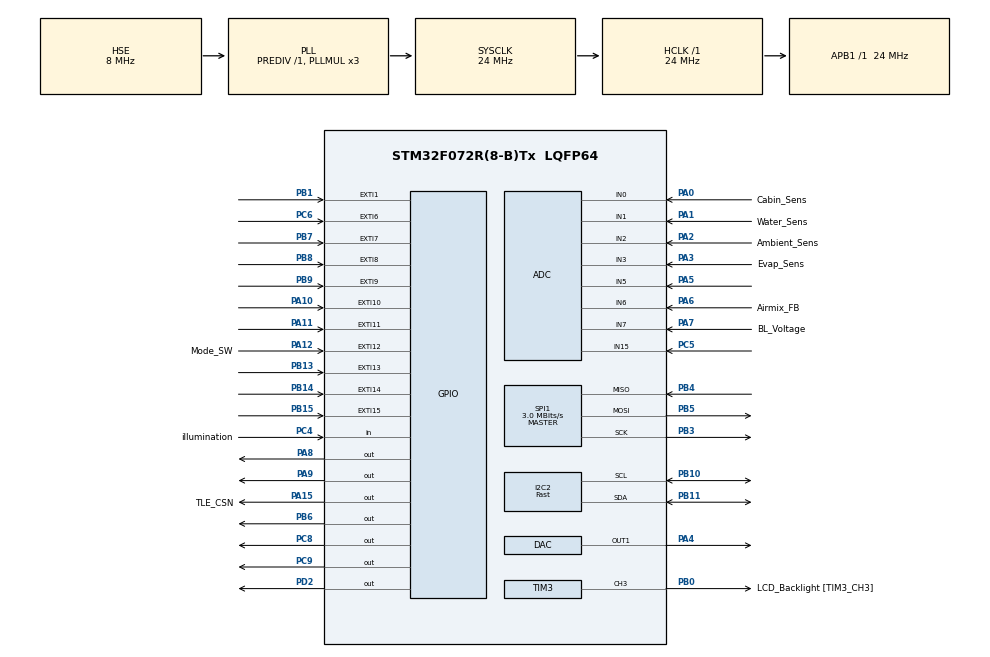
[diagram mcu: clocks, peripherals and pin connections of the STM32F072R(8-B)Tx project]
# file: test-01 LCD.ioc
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ADC.ClockPrescaler=ADC_CLOCK_SYNC_PCLK_DIV4
ADC.ContinuousConvMode=ENABLE
ADC.DMAContinuousRequests=ENABLE
ADC.ExternalTrigConv=ADC_EXTERNALTRIGCONV_T1_TRGO
ADC.Overrun=ADC_OVR_DATA_OVERWRITTEN
ADC.SamplingTime=ADC_SAMPLETIME_239CYCLES_5
Dma.ADC.0.Direction=DMA_PERIPH_TO_MEMORY
Dma.ADC.0.Instance=DMA1_Channel1
Dma.ADC.0.MemDataAlignment=DMA_MDATAALIGN_HALFWORD
Dma.ADC.0.MemInc=DMA_MINC_ENABLE
Dma.ADC.0.Mode=DMA_CIRCULAR
Dma.ADC.0.PeriphDataAlignment=DMA_PDATAALIGN_HALFWORD
Dma.ADC.0.PeriphInc=DMA_PINC_DISABLE
Dma.ADC.0.Priority=DMA_PRIORITY_LOW
Dma.Request0=ADC
I2C2.I2C_Speed_Mode=I2C_Fast
I2C2.Timing=0x00200C28
Mcu.Family=STM32F0
Mcu.Name=STM32F072R(8-B)Tx
Mcu.Package=LQFP64
NVIC.ADC1_COMP_IRQn=true\:0\:0\:false\:false\:true\:true\:true\:true
NVIC.DMA1_Channel1_IRQn=true\:0\:0\:true\:false\:true\:false\:true\:true
NVIC.EXTI0_1_IRQn=true\:0\:0\:false\:false\:true\:true\:true\:true
NVIC.EXTI4_15_IRQn=true\:0\:0\:false\:false\:true\:true\:true\:true
NVIC.TIM14_IRQn=true\:0\:0\:false\:false\:true\:true\:true\:true
NVIC.TIM15_IRQn=true\:0\:0\:false\:false\:true\:true\:true\:true
NVIC.TIM2_IRQn=true\:0\:0\:false\:false\:true\:true\:true\:true
NVIC.TIM6_DAC_IRQn=true\:0\:0\:false\:false\:true\:true\:true\:true
NVIC.TIM7_IRQn=true\:0\:0\:false\:false\:true\:true\:true\:true
PA0.GPIO_Label=Cabin_Sens
PA0.Mode=IN0
PA0.Signal=ADC_IN0
PA1.GPIO_Label=Water_Sens
PA1.Mode=IN1
PA1.Signal=ADC_IN1
PA10.GPIO_ModeDefaultEXTI=GPIO_MODE_IT_FALLING
PA10.GPIO_PuPd=GPIO_PULLUP
PA10.Signal=GPXTI10
PA11.GPIO_ModeDefaultEXTI=GPIO_MODE_IT_FALLING
PA11.GPIO_PuPd=GPIO_PULLUP
PA11.Signal=GPXTI11
PA12.GPIO_Label=Mode_SW
PA12.GPIO_ModeDefaultEXTI=GPIO_MODE_IT_FALLING
PA12.GPIO_PuPd=GPIO_PULLUP
PA12.Signal=GPXTI12
PA13.Mode=Serial_Wire
PA13.Signal=SYS_SWDIO
PA14.Mode=Serial_Wire
PA14.Signal=SYS_SWCLK
PA15.GPIO_Label=TLE_CSN
PA15.Signal=GPIO_Output
PA2.GPIO_Label=Ambient_Sens
PA2.Mode=IN2
PA2.Signal=ADC_IN2
PA3.GPIO_Label=Evap_Sens
PA3.Mode=IN3
PA3.Signal=ADC_IN3
PA4.Signal=COMP_DAC1_group
PA5.Mode=IN5
PA5.Signal=ADC_IN5
PA6.GPIO_Label=Airmix_FB
PA6.Mode=IN6
PA6.Signal=ADC_IN6
PA7.GPIO_Label=BL_Voltage
PA7.Mode=IN7
PA7.Signal=ADC_IN7
PA8.Signal=GPIO_Output
PA9.Signal=GPIO_Output
PB0.GPIO_Label=LCD_Backlight [TIM3_CH3]
PB0.Signal=S_TIM3_CH3
PB1.GPIO_ModeDefaultEXTI=GPIO_MODE_IT_FALLING
PB1.GPIO_PuPd=GPIO_PULLUP
PB1.Signal=GPXTI1
PB10.Mode=I2C
PB10.Signal=I2C2_SCL
PB11.Mode=I2C
PB11.Signal=I2C2_SDA
PB13.GPIO_ModeDefaultEXTI=GPIO_MODE_IT_FALLING
PB13.GPIO_PuPd=GPIO_PULLUP
PB13.Signal=GPXTI13
PB14.GPIO_ModeDefaultEXTI=GPIO_MODE_IT_FALLING
PB14.GPIO_PuPd=GPIO_PULLUP
PB14.Signal=GPXTI14
PB15.GPIO_ModeDefaultEXTI=GPIO_MODE_IT_FALLING
PB15.GPIO_PuPd=GPIO_PULLUP
PB15.Signal=GPXTI15
PB3.Mode=Full_Duplex_Master
PB3.Signal=SPI1_SCK
PB4.Mode=Full_Duplex_Master
PB4.Signal=SPI1_MISO
PB5.Mode=Full_Duplex_Master
PB5.Signal=SPI1_MOSI
PB6.Signal=GPIO_Output
PB7.GPIO_ModeDefaultEXTI=GPIO_MODE_IT_FALLING
PB7.GPIO_PuPd=GPIO_PULLUP
PB7.Signal=GPXTI7
PB8.GPIO_ModeDefaultEXTI=GPIO_MODE_IT_FALLING
PB8.GPIO_PuPd=GPIO_PULLUP
PB8.Signal=GPXTI8
PB9.GPIO_ModeDefaultEXTI=GPIO_MODE_IT_FALLING
PB9.GPIO_PuPd=GPIO_PULLUP
PB9.Signal=GPXTI9
PC4.GPIO_Label=illumination
PC4.Signal=GPIO_Input
PC5.Mode=IN15
PC5.Signal=ADC_IN15
PC6.GPIO_ModeDefaultEXTI=GPIO_MODE_IT_FALLING
PC6.GPIO_PuPd=GPIO_PULLUP
PC6.Signal=GPXTI6
PC8.Signal=GPIO_Output
PC9.Signal=GPIO_Output
PD2.Signal=GPIO_Output
PF0-OSC_IN.Mode=HSE-External-Oscillator
PF0-OSC_IN.Signal=RCC_OSC_IN
PF1-OSC_OUT.Mode=HSE-External-Oscillator
PF1-OSC_OUT.Signal=RCC_OSC_OUT
ProjectManager.HeapSize=0x200
ProjectManager.StackSize=0x400
ProjectManager.TargetToolchain=MDK-ARM V5.32
RCC.AHBFreq_Value=24000000
RCC.APB1Freq_Value=24000000
RCC.APB1TimFreq_Value=24000000
RCC.HCLKFreq_Value=24000000
RCC.PLLMUL=RCC_PLL_MUL3
RCC.PLLSourceVirtual=RCC_PLLSOURCE_HSE
RCC.SYSCLKFreq_VALUE=24000000
RCC.SYSCLKSource=RCC_SYSCLKSOURCE_PLLCLK
SH.COMP_DAC1_group.0=DAC_OUT1,DAC_OUT1
SH.S_TIM3_CH3.0=TIM3_CH3,PWM Generation3 CH3
SPI1.BaudRatePrescaler=SPI_BAUDRATEPRESCALER_8
SPI1.CLKPhase=SPI_PHASE_2EDGE
SPI1.CalculateBaudRate=3.0 MBits/s
SPI1.DataSize=SPI_DATASIZE_8BIT
SPI1.Direction=SPI_DIRECTION_2LINES
SPI1.FirstBit=SPI_FIRSTBIT_LSB
SPI1.Mode=SPI_MODE_MASTER
SPI1.VirtualType=VM_MASTER
TIM1.Period=100-1
TIM1.Prescaler=2400-1
TIM1.TIM_MasterOutputTrigger=TIM_TRGO_UPDATE
TIM14.Period=5000-1
TIM14.Prescaler=24000-1
TIM15.Period=3000-1
TIM15.Prescaler=24000-1
TIM2.Period=840000-1
TIM2.Prescaler=24000-1
TIM3.Channel-PWM\ Generation3\ CH3=TIM_CHANNEL_3
TIM3.Period=100-1
TIM3.Prescaler=240-1
TIM6.Period=15000-1
TIM6.Prescaler=24000-1
TIM7.Period=15000-1
TIM7.Prescaler=24000-1
VP_TIM14_VS_ClockSourceINT.Mode=Enable_Timer
VP_TIM15_VS_ClockSourceINT.Mode=Internal
VP_TIM1_VS_ClockSourceINT.Mode=Internal
VP_TIM2_VS_ClockSourceINT.Mode=Internal
VP_TIM3_VS_ClockSourceINT.Mode=Internal
VP_TIM6_VS_ClockSourceINT.Mode=Enable_Timer
VP_TIM7_VS_ClockSourceINT.Mode=Enable_Timer
board=custom

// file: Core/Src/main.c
/* USER CODE BEGIN Header */
/**
  ******************************************************************************
  * @file           : main.c
  * @brief          : Main program body
  ******************************************************************************
  * @attention
  *
  * Copyright (c) 2022 STMicroelectronics.
  * All rights reserved.
  *
  * This software is licensed under terms that can be found in the LICENSE file
  * in the root directory of this software component.
  * If no LICENSE file comes with this software, it is provided AS-IS.
  *
  ******************************************************************************
  */
/* USER CODE END Header */
#include "main.h"

/* USER CODE BEGIN Includes */
//#include "SP100_lcd.h"
#include "SP100_atc_ccu.h"

/* USER CODE END Includes */

 ADC_HandleTypeDef hadc;
DMA_HandleTypeDef hdma_adc;

DAC_HandleTypeDef hdac;

I2C_HandleTypeDef hi2c2;

SPI_HandleTypeDef hspi1;

TIM_HandleTypeDef htim1;
TIM_HandleTypeDef htim2;
TIM_HandleTypeDef htim3;
TIM_HandleTypeDef htim6;
TIM_HandleTypeDef htim7;
TIM_HandleTypeDef htim14;
TIM_HandleTypeDef htim15;

void SystemClock_Config(void);
static void MX_GPIO_Init(void);
static void MX_I2C2_Init(void);
static void MX_TIM3_Init(void);
static void MX_ADC_Init(void);
static void MX_DMA_Init(void);
static void MX_SPI1_Init(void);
static void MX_DAC_Init(void);
static void MX_TIM1_Init(void);
static void MX_TIM6_Init(void);
static void MX_TIM7_Init(void);
static void MX_TIM14_Init(void);
static void MX_TIM2_Init(void);
static void MX_TIM15_Init(void);

int main(void)
{
  /* USER CODE BEGIN 1 */

	// Agha Ye nokte kheyli mohem:7
	// 	DMA initesh bayad ghable ADC bashe...!!!!!!!
	MX_DMA_Init();
  /* USER CODE END 1 */

  /* MCU Configuration--------------------------------------------------------*/

  /* Reset of all peripherals, Initializes the Flash interface and the Systick. */
  HAL_Init();

  /* Configure the system clock */
  SystemClock_Config();

  /* Initialize all configured peripherals */
  MX_GPIO_Init();
  MX_I2C2_Init();
  MX_TIM3_Init();
  MX_ADC_Init();
  MX_DMA_Init();
  MX_SPI1_Init();
  MX_DAC_Init();
  MX_TIM1_Init();
  MX_TIM6_Init();
  MX_TIM7_Init();
  MX_TIM14_Init();
  MX_TIM2_Init();
  MX_TIM15_Init();
  /* USER CODE BEGIN 2 */
	//SP100_LCD_Init();
	//SP100_TLE_Init();
	SP100_CCU_Init();
	SP100_CCU_Infinite_Loop();
  /* USER CODE END 2 */

  /* Infinite loop */
  while (1)
  {

  }
}

void SystemClock_Config(void)
{
  RCC_OscInitTypeDef RCC_OscInitStruct = {0};
  RCC_ClkInitTypeDef RCC_ClkInitStruct = {0};

  /** Initializes the RCC Oscillators according to the specified parameters
  * in the RCC_OscInitTypeDef structure.
  */
  RCC_OscInitStruct.OscillatorType = RCC_OSCILLATORTYPE_HSE;
  RCC_OscInitStruct.HSEState = RCC_HSE_ON;
  RCC_OscInitStruct.PLL.PLLState = RCC_PLL_ON;
  RCC_OscInitStruct.PLL.PLLSource = RCC_PLLSOURCE_HSE;
  RCC_OscInitStruct.PLL.PLLMUL = RCC_PLL_MUL3;
  RCC_OscInitStruct.PLL.PREDIV = RCC_PREDIV_DIV1;
  if (HAL_RCC_OscConfig(&RCC_OscInitStruct) != HAL_OK)
  {
    Error_Handler();
  }

  /** Initializes the CPU, AHB and APB buses clocks
  */
  RCC_ClkInitStruct.ClockType = RCC_CLOCKTYPE_HCLK|RCC_CLOCKTYPE_SYSCLK
                              |RCC_CLOCKTYPE_PCLK1;
  RCC_ClkInitStruct.SYSCLKSource = RCC_SYSCLKSOURCE_PLLCLK;
  RCC_ClkInitStruct.AHBCLKDivider = RCC_SYSCLK_DIV1;
  RCC_ClkInitStruct.APB1CLKDivider = RCC_HCLK_DIV1;

  if (HAL_RCC_ClockConfig(&RCC_ClkInitStruct, FLASH_LATENCY_0) != HAL_OK)
  {
    Error_Handler();
  }
}

static void MX_ADC_Init(void)
{

  ADC_ChannelConfTypeDef sConfig = {0};

  /** Configure the global features of the ADC (Clock, Resolution, Data Alignment and number of conversion)
  */
  hadc.Instance = ADC1;
  hadc.Init.ClockPrescaler = ADC_CLOCK_SYNC_PCLK_DIV4;
  hadc.Init.Resolution = ADC_RESOLUTION_12B;
  hadc.Init.DataAlign = ADC_DATAALIGN_RIGHT;
  hadc.Init.ScanConvMode = ADC_SCAN_DIRECTION_FORWARD;
  hadc.Init.EOCSelection = ADC_EOC_SINGLE_CONV;
  hadc.Init.LowPowerAutoWait = DISABLE;
  hadc.Init.LowPowerAutoPowerOff = DISABLE;
  hadc.Init.ContinuousConvMode = ENABLE;
  hadc.Init.DiscontinuousConvMode = DISABLE;
  hadc.Init.ExternalTrigConv = ADC_EXTERNALTRIGCONV_T1_TRGO;
  hadc.Init.ExternalTrigConvEdge = ADC_EXTERNALTRIGCONVEDGE_RISING;
  hadc.Init.DMAContinuousRequests = ENABLE;
  hadc.Init.Overrun = ADC_OVR_DATA_OVERWRITTEN;
  if (HAL_ADC_Init(&hadc) != HAL_OK)
  {
    Error_Handler();
  }

  /** Configure for the selected ADC regular channel to be converted.
  */
  sConfig.Channel = ADC_CHANNEL_0;
  sConfig.Rank = ADC_RANK_CHANNEL_NUMBER;
  sConfig.SamplingTime = ADC_SAMPLETIME_239CYCLES_5;
  if (HAL_ADC_ConfigChannel(&hadc, &sConfig) != HAL_OK)
  {
    Error_Handler();
  }

  /** Configure for the selected ADC regular channel to be converted.
  */
  sConfig.Channel = ADC_CHANNEL_1;
  if (HAL_ADC_ConfigChannel(&hadc, &sConfig) != HAL_OK)
  {
    Error_Handler();
  }

  /** Configure for the selected ADC regular channel to be converted.
  */
  sConfig.Channel = ADC_CHANNEL_2;
  if (HAL_ADC_ConfigChannel(&hadc, &sConfig) != HAL_OK)
  {
    Error_Handler();
  }

  /** Configure for the selected ADC regular channel to be converted.
  */
  sConfig.Channel = ADC_CHANNEL_3;
  if (HAL_ADC_ConfigChannel(&hadc, &sConfig) != HAL_OK)
  {
    Error_Handler();
  }

  /** Configure for the selected ADC regular channel to be converted.
  */
  sConfig.Channel = ADC_CHANNEL_5;
  if (HAL_ADC_ConfigChannel(&hadc, &sConfig) != HAL_OK)
  {
    Error_Handler();
  }

  /** Configure for the selected ADC regular channel to be converted.
  */
  sConfig.Channel = ADC_CHANNEL_6;
  if (HAL_ADC_ConfigChannel(&hadc, &sConfig) != HAL_OK)
  {
    Error_Handler();
  }

  /** Configure for the selected ADC regular channel to be converted.
  */
  sConfig.Channel = ADC_CHANNEL_7;
  if (HAL_ADC_ConfigChannel(&hadc, &sConfig) != HAL_OK)
  {
    Error_Handler();
  }

  /** Configure for the selected ADC regular channel to be converted.
  */
  sConfig.Channel = ADC_CHANNEL_15;
  if (HAL_ADC_ConfigChannel(&hadc, &sConfig) != HAL_OK)
  {
    Error_Handler();
  }

}

static void MX_DAC_Init(void)
{

  DAC_ChannelConfTypeDef sConfig = {0};

  /** DAC Initialization
  */
  hdac.Instance = DAC;
  if (HAL_DAC_Init(&hdac) != HAL_OK)
  {
    Error_Handler();
  }

  /** DAC channel OUT1 config
  */
  sConfig.DAC_Trigger = DAC_TRIGGER_NONE;
  sConfig.DAC_OutputBuffer = DAC_OUTPUTBUFFER_ENABLE;
  if (HAL_DAC_ConfigChannel(&hdac, &sConfig, DAC_CHANNEL_1) != HAL_OK)
  {
    Error_Handler();
  }

}

static void MX_I2C2_Init(void)
{

  hi2c2.Instance = I2C2;
  hi2c2.Init.Timing = 0x00200C28;
  hi2c2.Init.OwnAddress1 = 0;
  hi2c2.Init.AddressingMode = I2C_ADDRESSINGMODE_7BIT;
  hi2c2.Init.DualAddressMode = I2C_DUALADDRESS_DISABLE;
  hi2c2.Init.OwnAddress2 = 0;
  hi2c2.Init.OwnAddress2Masks = I2C_OA2_NOMASK;
  hi2c2.Init.GeneralCallMode = I2C_GENERALCALL_DISABLE;
  hi2c2.Init.NoStretchMode = I2C_NOSTRETCH_DISABLE;
  if (HAL_I2C_Init(&hi2c2) != HAL_OK)
  {
    Error_Handler();
  }

  /** Configure Analogue filter
  */
  if (HAL_I2CEx_ConfigAnalogFilter(&hi2c2, I2C_ANALOGFILTER_ENABLE) != HAL_OK)
  {
    Error_Handler();
  }

  /** Configure Digital filter
  */
  if (HAL_I2CEx_ConfigDigitalFilter(&hi2c2, 0) != HAL_OK)
  {
    Error_Handler();
  }

}

static void MX_SPI1_Init(void)
{

  /* SPI1 parameter configuration*/
  hspi1.Instance = SPI1;
  hspi1.Init.Mode = SPI_MODE_MASTER;
  hspi1.Init.Direction = SPI_DIRECTION_2LINES;
  hspi1.Init.DataSize = SPI_DATASIZE_8BIT;
  hspi1.Init.CLKPolarity = SPI_POLARITY_LOW;
  hspi1.Init.CLKPhase = SPI_PHASE_2EDGE;
  hspi1.Init.NSS = SPI_NSS_SOFT;
  hspi1.Init.BaudRatePrescaler = SPI_BAUDRATEPRESCALER_8;
  hspi1.Init.FirstBit = SPI_FIRSTBIT_LSB;
  hspi1.Init.TIMode = SPI_TIMODE_DISABLE;
  hspi1.Init.CRCCalculation = SPI_CRCCALCULATION_DISABLE;
  hspi1.Init.CRCPolynomial = 7;
  hspi1.Init.CRCLength = SPI_CRC_LENGTH_DATASIZE;
  hspi1.Init.NSSPMode = SPI_NSS_PULSE_DISABLE;
  if (HAL_SPI_Init(&hspi1) != HAL_OK)
  {
    Error_Handler();
  }

}

static void MX_TIM1_Init(void)
{

  TIM_ClockConfigTypeDef sClockSourceConfig = {0};
  TIM_MasterConfigTypeDef sMasterConfig = {0};

  htim1.Instance = TIM1;
  htim1.Init.Prescaler = 2400-1;
  htim1.Init.CounterMode = TIM_COUNTERMODE_UP;
  htim1.Init.Period = 100-1;
  htim1.Init.ClockDivision = TIM_CLOCKDIVISION_DIV1;
  htim1.Init.RepetitionCounter = 0;
  htim1.Init.AutoReloadPreload = TIM_AUTORELOAD_PRELOAD_DISABLE;
  if (HAL_TIM_Base_Init(&htim1) != HAL_OK)
  {
    Error_Handler();
  }
  sClockSourceConfig.ClockSource = TIM_CLOCKSOURCE_INTERNAL;
  if (HAL_TIM_ConfigClockSource(&htim1, &sClockSourceConfig) != HAL_OK)
  {
    Error_Handler();
  }
  sMasterConfig.MasterOutputTrigger = TIM_TRGO_UPDATE;
  sMasterConfig.MasterSlaveMode = TIM_MASTERSLAVEMODE_DISABLE;
  if (HAL_TIMEx_MasterConfigSynchronization(&htim1, &sMasterConfig) != HAL_OK)
  {
    Error_Handler();
  }

}

static void MX_TIM2_Init(void)
{

  TIM_ClockConfigTypeDef sClockSourceConfig = {0};
  TIM_MasterConfigTypeDef sMasterConfig = {0};

  htim2.Instance = TIM2;
  htim2.Init.Prescaler = 24000-1;
  htim2.Init.CounterMode = TIM_COUNTERMODE_UP;
  htim2.Init.Period = 840000-1;
  htim2.Init.ClockDivision = TIM_CLOCKDIVISION_DIV1;
  htim2.Init.AutoReloadPreload = TIM_AUTORELOAD_PRELOAD_DISABLE;
  if (HAL_TIM_Base_Init(&htim2) != HAL_OK)
  {
    Error_Handler();
  }
  sClockSourceConfig.ClockSource = TIM_CLOCKSOURCE_INTERNAL;
  if (HAL_TIM_ConfigClockSource(&htim2, &sClockSourceConfig) != HAL_OK)
  {
    Error_Handler();
  }
  sMasterConfig.MasterOutputTrigger = TIM_TRGO_RESET;
  sMasterConfig.MasterSlaveMode = TIM_MASTERSLAVEMODE_DISABLE;
  if (HAL_TIMEx_MasterConfigSynchronization(&htim2, &sMasterConfig) != HAL_OK)
  {
    Error_Handler();
  }

}

static void MX_TIM3_Init(void)
{

  TIM_ClockConfigTypeDef sClockSourceConfig = {0};
  TIM_MasterConfigTypeDef sMasterConfig = {0};
  TIM_OC_InitTypeDef sConfigOC = {0};

  htim3.Instance = TIM3;
  htim3.Init.Prescaler = 240-1;
  htim3.Init.CounterMode = TIM_COUNTERMODE_UP;
  htim3.Init.Period = 100-1;
  htim3.Init.ClockDivision = TIM_CLOCKDIVISION_DIV1;
  htim3.Init.AutoReloadPreload = TIM_AUTORELOAD_PRELOAD_DISABLE;
  if (HAL_TIM_Base_Init(&htim3) != HAL_OK)
  {
    Error_Handler();
  }
  sClockSourceConfig.ClockSource = TIM_CLOCKSOURCE_INTERNAL;
  if (HAL_TIM_ConfigClockSource(&htim3, &sClockSourceConfig) != HAL_OK)
  {
    Error_Handler();
  }
  if (HAL_TIM_PWM_Init(&htim3) != HAL_OK)
  {
    Error_Handler();
  }
  sMasterConfig.MasterOutputTrigger = TIM_TRGO_RESET;
  sMasterConfig.MasterSlaveMode = TIM_MASTERSLAVEMODE_DISABLE;
  if (HAL_TIMEx_MasterConfigSynchronization(&htim3, &sMasterConfig) != HAL_OK)
  {
    Error_Handler();
  }
  sConfigOC.OCMode = TIM_OCMODE_PWM1;
  sConfigOC.Pulse = 0;
  sConfigOC.OCPolarity = TIM_OCPOLARITY_HIGH;
  sConfigOC.OCFastMode = TIM_OCFAST_DISABLE;
  if (HAL_TIM_PWM_ConfigChannel(&htim3, &sConfigOC, TIM_CHANNEL_3) != HAL_OK)
  {
    Error_Handler();
  }
  HAL_TIM_MspPostInit(&htim3);

}

static void MX_TIM6_Init(void)
{

  TIM_MasterConfigTypeDef sMasterConfig = {0};

  htim6.Instance = TIM6;
  htim6.Init.Prescaler = 24000-1;
  htim6.Init.CounterMode = TIM_COUNTERMODE_UP;
  htim6.Init.Period = 15000-1;
  htim6.Init.AutoReloadPreload = TIM_AUTORELOAD_PRELOAD_DISABLE;
  if (HAL_TIM_Base_Init(&htim6) != HAL_OK)
  {
    Error_Handler();
  }
  sMasterConfig.MasterOutputTrigger = TIM_TRGO_RESET;
  sMasterConfig.MasterSlaveMode = TIM_MASTERSLAVEMODE_DISABLE;
  if (HAL_TIMEx_MasterConfigSynchronization(&htim6, &sMasterConfig) != HAL_OK)
  {
    Error_Handler();
  }

}

static void MX_TIM7_Init(void)
{

  TIM_MasterConfigTypeDef sMasterConfig = {0};

  htim7.Instance = TIM7;
  htim7.Init.Prescaler = 24000-1;
  htim7.Init.CounterMode = TIM_COUNTERMODE_UP;
  htim7.Init.Period = 15000-1;
  htim7.Init.AutoReloadPreload = TIM_AUTORELOAD_PRELOAD_DISABLE;
  if (HAL_TIM_Base_Init(&htim7) != HAL_OK)
  {
    Error_Handler();
  }
  sMasterConfig.MasterOutputTrigger = TIM_TRGO_RESET;
  sMasterConfig.MasterSlaveMode = TIM_MASTERSLAVEMODE_DISABLE;
  if (HAL_TIMEx_MasterConfigSynchronization(&htim7, &sMasterConfig) != HAL_OK)
  {
    Error_Handler();
  }

}

static void MX_TIM14_Init(void)
{

  htim14.Instance = TIM14;
  htim14.Init.Prescaler = 24000-1;
  htim14.Init.CounterMode = TIM_COUNTERMODE_UP;
  htim14.Init.Period = 5000-1;
  htim14.Init.ClockDivision = TIM_CLOCKDIVISION_DIV1;
  htim14.Init.AutoReloadPreload = TIM_AUTORELOAD_PRELOAD_DISABLE;
  if (HAL_TIM_Base_Init(&htim14) != HAL_OK)
  {
    Error_Handler();
  }

}

static void MX_TIM15_Init(void)
{

  TIM_ClockConfigTypeDef sClockSourceConfig = {0};
  TIM_MasterConfigTypeDef sMasterConfig = {0};

  htim15.Instance = TIM15;
  htim15.Init.Prescaler = 24000-1;
  htim15.Init.CounterMode = TIM_COUNTERMODE_UP;
  htim15.Init.Period = 3000-1;
  htim15.Init.ClockDivision = TIM_CLOCKDIVISION_DIV1;
  htim15.Init.RepetitionCounter = 0;
  htim15.Init.AutoReloadPreload = TIM_AUTORELOAD_PRELOAD_DISABLE;
  if (HAL_TIM_Base_Init(&htim15) != HAL_OK)
  {
    Error_Handler();
  }
  sClockSourceConfig.ClockSource = TIM_CLOCKSOURCE_INTERNAL;
  if (HAL_TIM_ConfigClockSource(&htim15, &sClockSourceConfig) != HAL_OK)
  {
    Error_Handler();
  }
  sMasterConfig.MasterOutputTrigger = TIM_TRGO_RESET;
  sMasterConfig.MasterSlaveMode = TIM_MASTERSLAVEMODE_DISABLE;
  if (HAL_TIMEx_MasterConfigSynchronization(&htim15, &sMasterConfig) != HAL_OK)
  {
    Error_Handler();
  }

}

static void MX_DMA_Init(void)
{

  /* DMA controller clock enable */
  __HAL_RCC_DMA1_CLK_ENABLE();

  /* DMA interrupt init */
  /* DMA1_Channel1_IRQn interrupt configuration */
  HAL_NVIC_SetPriority(DMA1_Channel1_IRQn, 0, 0);
  HAL_NVIC_EnableIRQ(DMA1_Channel1_IRQn);

}

static void MX_GPIO_Init(void)
{
  GPIO_InitTypeDef GPIO_InitStruct = {0};

  /* GPIO Ports Clock Enable */
  __HAL_RCC_GPIOF_CLK_ENABLE();
  __HAL_RCC_GPIOA_CLK_ENABLE();
  __HAL_RCC_GPIOC_CLK_ENABLE();
  __HAL_RCC_GPIOB_CLK_ENABLE();
  __HAL_RCC_GPIOD_CLK_ENABLE();

  /*Configure GPIO pin Output Level */
  HAL_GPIO_WritePin(GPIOC, GPIO_PIN_8|GPIO_PIN_9, GPIO_PIN_RESET);

  /*Configure GPIO pin Output Level */
  HAL_GPIO_WritePin(GPIOA, GPIO_PIN_8|GPIO_PIN_9|TLE_CSN_Pin, GPIO_PIN_RESET);

  /*Configure GPIO pin Output Level */
  HAL_GPIO_WritePin(GPIOD, GPIO_PIN_2, GPIO_PIN_RESET);

  /*Configure GPIO pin Output Level */
  HAL_GPIO_WritePin(GPIOB, GPIO_PIN_6, GPIO_PIN_RESET);

  /*Configure GPIO pin : illumination_Pin */
  GPIO_InitStruct.Pin = illumination_Pin;
  GPIO_InitStruct.Mode = GPIO_MODE_INPUT;
  GPIO_InitStruct.Pull = GPIO_NOPULL;
  HAL_GPIO_Init(illumination_GPIO_Port, &GPIO_InitStruct);

  /*Configure GPIO pins : PB1 PB13 PB14 PB15
                           PB7 PB8 PB9 */
  GPIO_InitStruct.Pin = GPIO_PIN_1|GPIO_PIN_13|GPIO_PIN_14|GPIO_PIN_15
                          |GPIO_PIN_7|GPIO_PIN_8|GPIO_PIN_9;
  GPIO_InitStruct.Mode = GPIO_MODE_IT_FALLING;
  GPIO_InitStruct.Pull = GPIO_PULLUP;
  HAL_GPIO_Init(GPIOB, &GPIO_InitStruct);

  /*Configure GPIO pin : PC6 */
  GPIO_InitStruct.Pin = GPIO_PIN_6;
  GPIO_InitStruct.Mode = GPIO_MODE_IT_FALLING;
  GPIO_InitStruct.Pull = GPIO_PULLUP;
  HAL_GPIO_Init(GPIOC, &GPIO_InitStruct);

  /*Configure GPIO pins : PC8 PC9 */
  GPIO_InitStruct.Pin = GPIO_PIN_8|GPIO_PIN_9;
  GPIO_InitStruct.Mode = GPIO_MODE_OUTPUT_PP;
  GPIO_InitStruct.Pull = GPIO_NOPULL;
  GPIO_InitStruct.Speed = GPIO_SPEED_FREQ_LOW;
  HAL_GPIO_Init(GPIOC, &GPIO_InitStruct);

  /*Configure GPIO pins : PA8 PA9 TLE_CSN_Pin */
  GPIO_InitStruct.Pin = GPIO_PIN_8|GPIO_PIN_9|TLE_CSN_Pin;
  GPIO_InitStruct.Mode = GPIO_MODE_OUTPUT_PP;
  GPIO_InitStruct.Pull = GPIO_NOPULL;
  GPIO_InitStruct.Speed = GPIO_SPEED_FREQ_LOW;
  HAL_GPIO_Init(GPIOA, &GPIO_InitStruct);

  /*Configure GPIO pins : PA10 PA11 Mode_SW_Pin */
  GPIO_InitStruct.Pin = GPIO_PIN_10|GPIO_PIN_11|Mode_SW_Pin;
  GPIO_InitStruct.Mode = GPIO_MODE_IT_FALLING;
  GPIO_InitStruct.Pull = GPIO_PULLUP;
  HAL_GPIO_Init(GPIOA, &GPIO_InitStruct);

  /*Configure GPIO pin : PD2 */
  GPIO_InitStruct.Pin = GPIO_PIN_2;
  GPIO_InitStruct.Mode = GPIO_MODE_OUTPUT_PP;
  GPIO_InitStruct.Pull = GPIO_NOPULL;
  GPIO_InitStruct.Speed = GPIO_SPEED_FREQ_LOW;
  HAL_GPIO_Init(GPIOD, &GPIO_InitStruct);

  /*Configure GPIO pin : PB6 */
  GPIO_InitStruct.Pin = GPIO_PIN_6;
  GPIO_InitStruct.Mode = GPIO_MODE_OUTPUT_PP;
  GPIO_InitStruct.Pull = GPIO_NOPULL;
  GPIO_InitStruct.Speed = GPIO_SPEED_FREQ_LOW;
  HAL_GPIO_Init(GPIOB, &GPIO_InitStruct);

  /* EXTI interrupt init*/
  HAL_NVIC_SetPriority(EXTI0_1_IRQn, 0, 0);
  HAL_NVIC_EnableIRQ(EXTI0_1_IRQn);

  HAL_NVIC_SetPriority(EXTI4_15_IRQn, 0, 0);
  HAL_NVIC_EnableIRQ(EXTI4_15_IRQn);

}

void Error_Handler(void)
{
  __disable_irq();
  while (1)
  {
  }
}
